# pse84 register map
Vendor: Cypress Semiconductor; Series: PSE84; File version: 1.0
CPU: CM33 r0p1, little endian, MPU, FPU, VTOR, 3 interrupt priority bits
Registers are 32-bit, read-write, reset 0x0 unless marked. A register's access mark holds for its fields unless they carry their own. Offsets are from the block's base; [hi:lo] are bit positions; lines under a group give offsets from that group; {n}, {i} and the like mark numbered series; 'fields as' and 'values as' point back to an identical list.

## SOCMEM — SoC memory
Base 0x44640000
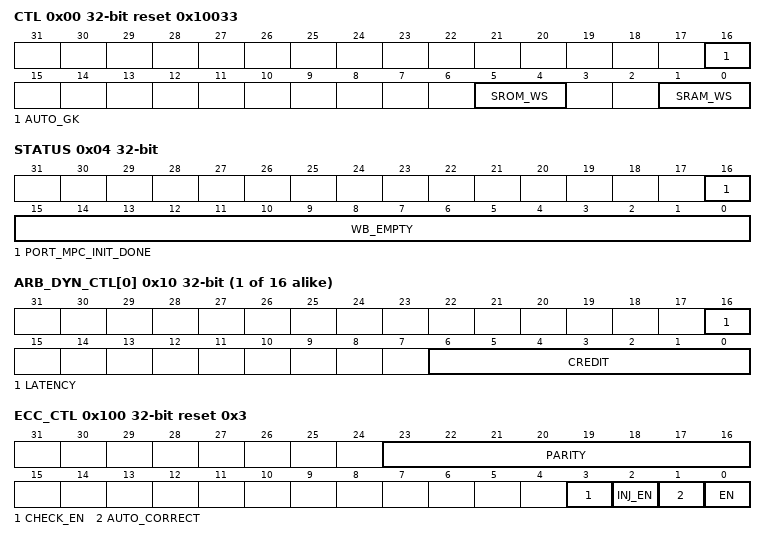
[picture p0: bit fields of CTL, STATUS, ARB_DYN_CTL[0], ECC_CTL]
0x00 CTL reset 0x10033 — Control
  [16] AUTO_GK — Automatic gate keeper control: '0': Disabled. '1': Enabled. Before every MMIO register write, ALL ports are automatically closed. After the MMIO register write, the gate keeper control defaults to GK_CTL.OPEN.
  [5:4] SROM_WS — Wait states.
    {v}=WS_{v} (N/A) (v=0..3)
  [1:0] SRAM_WS — Wait states.
    {v}=WS_{v} (N/A) (v=0..3)
0x04 STATUS ro (reset mask 0x10000)
  [16] PORT_MPC_INIT_DONE — Port MPC SRAM initialisation done. It is a combined single initialisation done for all the ports mpc sram.
  [15:0] WB_EMPTY — SRAM bank write buffer empty
0x08 GK_CTL — Gate keeper control
  [15:0] OPEN — Port gate keeper control: '0': Close port request. Finishes ongoing AMBA transactions, but does not accept new AMBA transactions. '1': Open port request. Note: GK_CTL allows for the creation of atomic sequences (from the perspective of AMBA transactions) of MMIO register writes. Note: gate keeper control is used to change MMIO register settings in an active system (per TZC400).
0x0C GK_STATUS ro — Gate keeper status
  [15:0] OPEN — Port gate keeper status '0': Port is closed. A port may be closed under SW MMIO control (GK_CTL) or under HW system control '1': Port is open. Note: gate keeper control is used to change MMIO register settings in an active system (per TZC400).
{0x10+4i} ARB_DYN_CTL[{i}] (i=0..15) — Port arbitration control
  [16] LATENCY — Specifies if the port is latency sensitive. '0': Non latency sensitive or less latency sensitive (e.g. a DMA controller). '1': Latency sensitive (e.g. a CPU or a real-time master such as a sound or display controller). As described above, the scheduler favors latency sensitive masters over non latency sensitive masters.
  [6:0] CREDIT — Port account increment. Value in the range [0, 127]. Total available SRAM/SROM bank bandwidth is partitioned into 128 partitions. The CREDIT value specifies what guaranteed relative bandwidth is assigned to the port. E.g., when CREDIT is '32', 25 percent of the relative bandwidth is assigned to the port. Note that for absolute bandwidth, the SRAM/SROM frequency and wait states need to be taken into account as well. An arbiter/scheduler operation is performed when one or more port requests for a SRAM/SROM bank are present and the SRAM/SROM bank is available for a new request. Each SRAM/SROM bank has a dedicated scheduler. The scheduler uses port account values: 9-bit values in the range [0, 511]. The port account values identify: - Non credit-worthy ports (account value in the range [0, 255]). - Credit-worthy ports (account value in the range [256, 511]). In addition, each port is specified to be either non (less) latency sensitive or latency sensitive (LATENCY). A scheduler operation is defined as follows: IF ('Any requesting port is a credit-worthy, latency port') 'Select port with lowest index from requesting, credit-worthy, latency ports' ELSE IF ('Any requesting port is a credit-worthy, non latency port') 'Select port with lowest index from requesting, credit-worthy, non latency ports' ELSE IF ('Any requesting port is a non credit-worthy, latency port') 'Select port with lowest index from requesting, non credit-worthy, latency ports' ELSE IF ('Any requesting port is a non credit-worthy, non latency port') 'Select port with lowest index from requesting, non credit-worthy, non latency ports' After a scheduler operation, account values are updated: - The selected port's account is incremented by CREDIT and decremented with '128'. If ECC is enabled AND the transaction was a partial write, an additional '128' is decremented, because two transactions (read-modify-write) are needed to change the ECC. Clipping to '0' is performed to prevent negative values. - Non-selected port account are increment by CREDIT, if the current account value is less than '256'. Otherwise, the port account value is not updated.
0x60 MPC_READ_PORT_CTL — MPC MMIO read port index control
  [3:0] INDEX — specifies port index for any MPC read access using SOCMEM.SRAM_MPC/SROM_MPC. 0- Any SW MPC MMIO read through SOCMEM.SRAM/SROM_MPC is from port-0. 1- Any SW MPC MMIO read through SOCMEM.SRAM/SROM_MPC is from port-1. . . 15- Any SW MPC MMIO read through SOCMEM.SRAM/SROM_MPC is from port-15. Note that INDEX field value programmed by SW must be between 0 and one less than number of configured SOCMEM ports (number of ports is design time config option using parameter PORT_NR). IMPORTANT: When MPC.CTRL.AUTO_INC is 1, each read access will auto-increment MPC.BLK_IDX in the port specified by MPC_READ_PORT_CTL.INDEX; not all ports are updated. Each write access will auto-increment MPC.BLK_IDX.VALUE in all ports. When MPC.CTRL.AUTO_INC is 1, to ensure that all ports are initialized correctly, write to MPC.BLK_IDX.VALUE before any series of writes to MPC.BLK_LUT. Writing to MPC.BLK_IDX.VALUE sets the index in all ports to the same value.
0x100 ECC_CTL reset 0x3 — ECC control
  [23:16] PARITY — Injected parity.
  [3] CHECK_EN — ECC checking enable: '0': Disabled. No ECC checking and associated bus errors. No fault reporting. Intended for SRAM initialization. '1': Enabled. Note: This field is ignored when EN is '0'.
  [2] INJ_EN — ECC parity injection: '0': Disabled. '1': Enabled. Instead of calculating the parity from the transfer's write data, the parity is taken from PARITY upon a match of the transfer's write address with ECC_MATCH.WORD_ADDR (no match is performed on the transfer's write strobes/mask). Note: Parity injection invalidates the write buffer for this word address. If only a part of 64-bit data word is written AND consistency should be maintained, STATUS.ALL_WB_EMPTY is '1' should be checked before. Note: This field is ignored when EN is '0'.
  [1] AUTO_CORRECT — ECC auto correction: '0': Disabled. Corrected ECC errors are ONLY HW corrected 'on-the-fly' (not corrected in the SRAM). Fault reporting is enabled. '1': Enabled. Correctable ECC errors are HW corrected 'on-the-fly' and in the SRAM, without CPU intervention. Fault reporting is enabled. Note: This field is ignored when EN is '0' or when CHECK_EN is '0'.
  [0] EN — ECC enable: '0': Disabled. '1': Enabled.
    0=ECC_DISABLED (N/A); 1=ECC_ENABLED (N/A)
0x104 ECC_MATCH
  [23:3] WORD_ADDR — Specifies the 8-Byte word address where a specific parity is injected. - On a write transfer to this word address, the parity (ECC_CTL.PARITY) is injected (if ECC_CTL.INJ_EN is '1').
0x110 WOUNDING
  [2:0] WOUND — Indicates the amount of accessible SRAM in this device. The value in this field is effectively write-once (it is only possible to set bits to '1', not clear them to '0'). Accesses to non-accessible SRAM return a bus error. Wounding control is rounded to next power of two bytes. '0': entire memory accessible '1': first 1/2 of the memory accessible. '2': first 1/4 of the memory accessible. '3': first 1/8 of the memory accessible. '4': first 1/16 of the memory accessible. '5': first 1/32 of the memory accessible. '6': first 1/64 of the memory accessible. '7': first 1/128 of the memory accessible.
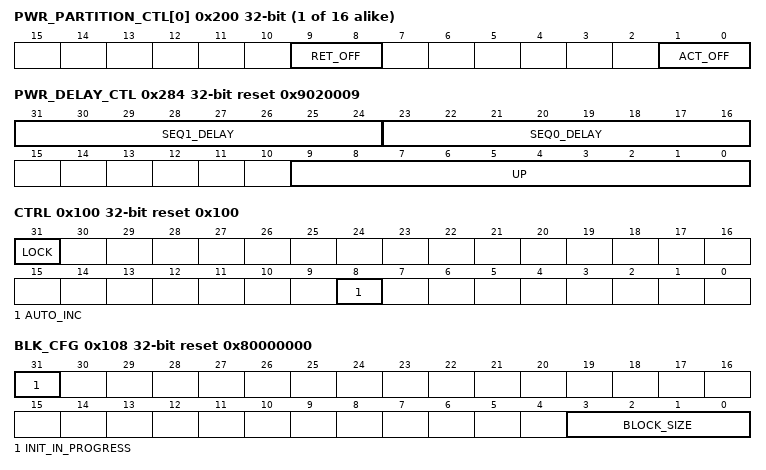
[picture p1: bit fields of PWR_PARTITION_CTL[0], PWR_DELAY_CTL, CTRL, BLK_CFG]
{0x200+4i} PWR_PARTITION_CTL[{i}] (i=0..15) — SRAM partition power control
  [9:8] RET_OFF, [1:0] ACT_OFF
0x280 PWR_PARTITION_CTL_LOCK reset 0x3 — SRAM power partition control Lock
  [1:0] PWR_PARTITION_CTL_LOCK — Prohibits Read/Write access to PWR_PARTITION_CTL register when this field is not equal to 0. Requires at least two different writes to unlock. Note that this field is 2 bits to force multiple writes only. By default AHB reads/writes to PWR_PARTITION_CTL register are locked.
    0=NO_CHG (No effect); 1=CLR0 (Clears bit 0); 2=CLR1 (Clears bit 1); 3=SET01 (Sets both bits 0 and 1)
0x284 PWR_DELAY_CTL reset 0x9020009 — SRAM power switch power up & sequence delay
  [31:24] SEQ1_DELAY — Number of IMO clock cycles delay needed for sequence-1 of SRAM power transition
  [23:16] SEQ0_DELAY — Number of IMO clock cycles delay needed for sequence-0 of SRAM power transition
  [9:0] UP — Number of IMO clock cycles delay needed after power domain power up
0x288 PWR_STATUS ro reset 0x1 — SRAM power status
  [0] PWR_DONE — After a PWR_PARTITION_CTL.OFF change this flag indicates if the new power mode has taken effect or not. 1: Indicates change is effective; 0: Indicates change is in progress;
0x2000 SRAM group — SRAM MPC
  0x00 MPC group — MPC Memory Protection Controller registers
    0x00 CFG — Config register with error response, RegionID PPC_MPC_MAIN is the security owner PC. The error response configuration is located in CFG.RESPONSE, only one such configuration exists applying to all protection contexts in the system.
      [4] RESPONSE — Response Configuration for Security and PC violations 0: Read-Zero Write Ignore (RAZ/WI) 1: Bus Error
    0x100 CTRL reset 0x100 — Control register with lock bit and auto-increment only (Separate CTRL for each PC depends on access_pc)
      [31] LOCK — Security lockdown for this protection context. Software can set this bit but not clear it once set. When set, write operations to BLK_LUT are not possible from this protection context. Setting LOCK also blocks writes to CTRL itself (for that PC copy). All writes are ignored.
      [8] AUTO_INC — Auto-increment BLK_IDX by 1 for this protection context as a side effect of each read/write access to BLK_LUT
    0x104 BLK_MAX ro — Max value of block-based index register
      [31:0] VALUE — Maximum value of block-based index register. The number and size blocks in an MPC is design time configurable and for embedded memories defaults to covering the entire memory using 4kB blocks; See product datasheet for details on protection of external memories.
    0x108 BLK_CFG ro reset 0x80000000 — Block size & initialization in progress
      [31] INIT_IN_PROGRESS — During initialization INIT_IN_PROGRESS is '1' and MMIO register accesses to BLK_LUT is blocked (BLK_IDX increment is also ignored). The block attributes are retained in DeepSleep (and obviously Active) power mode. Initialization is only required from a power mode in which the block attributes are not retained. E.g., initialization is required for a cold boot (after a Power-on-Reset). HW initializes the block attributes: the NS attributes are set to '0' (secure), the R attributes are set to '1' (read access allowed) and the W attributes are set to '1' (write access allowed). During initialization, the MPC supports memory accesses (memory accesses are NOT blocked) with the initialization block attribute values as mentioned above. This e.g. allows MPC initialization to proceed in parallel with boot program memory accesses (as opposed to serializing the two), improving device boot time.
      [3:0] BLOCK_SIZE — Block size of individually protected blocks (0: 32B, 1: 64B, ... up to 15: 1MB) Block size= (1<<(BLOCK_SIZE+5)) The number and size blocks in an MPC is design time configurable and for embedded memories defaults to covering the entire memory using 4kB blocks; see product datasheet for details on protection of external memories.
    0x10C BLK_IDX — Index of 32-block group accessed through BLK_LUT (Separate IDX for each PC depending on access_pc)
      [31:0] VALUE — Index value for accessing block-based lookup table using BLK_LUT. Programming out of LUT range is an user error and it loops back to '0' once overflow occurs.
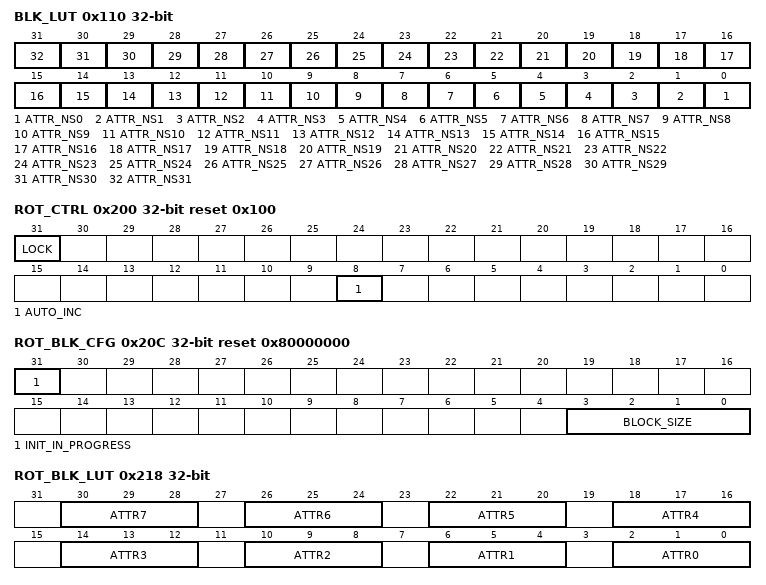
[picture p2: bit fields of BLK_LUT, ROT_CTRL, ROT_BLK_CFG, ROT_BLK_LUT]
    0x110 BLK_LUT — NS status for 32 blocks at BLK_IDX with PC=<access_pc>
      [n] ATTR_NS{n} (n=0..31) — NS bit for block {n} based on BLK_IDX
    0x200 ROT_CTRL reset 0x100 — Control register with lock bit and auto-increment only
      [31] LOCK — Security lockdown for the root-of-trust configuration registers. Software can set this bit but not clear it once set. When set, write operations to ROT_BLK_LUT are not possible. Write is ignored.
      [8] AUTO_INC — Auto-increment BLK_IDX by 1 for each read/write of ROT_BLK_LUT
    0x208 ROT_BLK_MAX ro — Max value of block-based index register for ROT
      [31:0] VALUE — Maximum value of block-based index register. The number and size blocks in an MPC is design time configurable and for embedded memories defaults to covering the entire memory using 4kB blocks; see product datasheet for details on protection of external memories.
    0x20C ROT_BLK_CFG ro reset 0x80000000 — Same as BLK_CFG
      [31] INIT_IN_PROGRESS — During initialization INIT_IN_PROGRESS is '1' and MMIO register accesses to ROT_BLK_LUT is RAZWI. The block attributes are retained in DeepSleep (and obviously Active) power mode. Initialization is only required from a power mode in which the block attributes are not retained. E.g., initialization is required for a cold boot (after a Power-on-Reset). HW initializes the block attributes: the NS attributes are set to '0' (secure), the R attributes are set to '1' (read access allowed) and the W attributes are set to '1' (write access allowed). During initialization, the MPC supports memory accesses (memory accesses are NOT blocked) with the initialization block attribute values as mentioned above. This e.g. allows MPC initialization to proceed in parallel with boot program memory accesses (as opposed to serializing the two), improving device boot time.
      [3:0] BLOCK_SIZE — Block size of individually protected blocks (0: 32B, 1: 64B, ...up to 15:1MB) Block size= (1<<(BLOCK_SIZE+5)) The number and size blocks in an MPC is design time configurable and for embedded memories defaults to covering the entire memory using 4kB blocks; see product datasheet for details on protection of external memories.
    0x210 ROT_BLK_IDX — Index of 8-block group accessed through ROT_BLK_LUT_*
      [31:0] VALUE — Index value for accessing block-based lookup table using ROT_BLK_LUT. Programming out of LUT range is an user error and it loops back to '0' once overflow occurs.
    0x214 ROT_BLK_PC — Protection context of 8-block group accesses through ROT_BLK_LUT
      [3:0] PC — Specify PC values for ROT_BLK_IDX and ROT_BLK_LUT
    0x218 ROT_BLK_LUT — (R,W,NS) bits for 8 blocks at ROT_BLK_IDX for PC=ROT_BKL_PC
      [4n+2:4n] ATTR{n} (n=0..7) — W/R/NS bits for block {n} indicated by ROT_BLK_IDX for ROT_BLK_PC PC
0x3000 SROM group — SROM MPC
  0x00 MPC group — MPC Memory Protection Controller registers
    0x00 CFG — Config register with error response, RegionID PPC_MPC_MAIN is the security owner PC. The error response configuration is located in CFG.RESPONSE, only one such configuration exists applying to all protection contexts in the system.
      fields as SRAM.MPC.CFG
    0x100 CTRL reset 0x100 — Control register with lock bit and auto-increment only (Separate CTRL for each PC depends on access_pc)
      fields as SRAM.MPC.CTRL
    0x104 BLK_MAX ro — Max value of block-based index register
      fields as SRAM.MPC.BLK_MAX
    0x108 BLK_CFG ro reset 0x80000000 — Block size & initialization in progress
      fields as SRAM.MPC.BLK_CFG
    0x10C BLK_IDX — Index of 32-block group accessed through BLK_LUT (Separate IDX for each PC depending on access_pc)
      fields as SRAM.MPC.BLK_IDX
    0x110 BLK_LUT — NS status for 32 blocks at BLK_IDX with PC=<access_pc>
      [n] ATTR_NS{n} (n=0..31) — NS bit for block {n} based on BLK_IDX
    0x200 ROT_CTRL reset 0x100 — Control register with lock bit and auto-increment only
      fields as SRAM.MPC.ROT_CTRL
    0x208 ROT_BLK_MAX ro — Max value of block-based index register for ROT
      fields as SRAM.MPC.ROT_BLK_MAX
    0x20C ROT_BLK_CFG ro reset 0x80000000 — Same as BLK_CFG
      fields as SRAM.MPC.ROT_BLK_CFG
    0x210 ROT_BLK_IDX — Index of 8-block group accessed through ROT_BLK_LUT_*
      fields as SRAM.MPC.ROT_BLK_IDX
    0x214 ROT_BLK_PC — Protection context of 8-block group accesses through ROT_BLK_LUT
      [3:0] PC — Specify PC values for ROT_BLK_IDX and ROT_BLK_LUT
    0x218 ROT_BLK_LUT — (R,W,NS) bits for 8 blocks at ROT_BLK_IDX for PC=ROT_BKL_PC
      fields as SRAM.MPC.ROT_BLK_LUT
{0x10000+0x1000*i} PORT_STRUCT[{i}] (i=0..4) group — Port structure
  0x00 PATCH_CTL — Patch control
    [31] ENABLED — Patching enable: '0': Disabled. '1': Enabled.
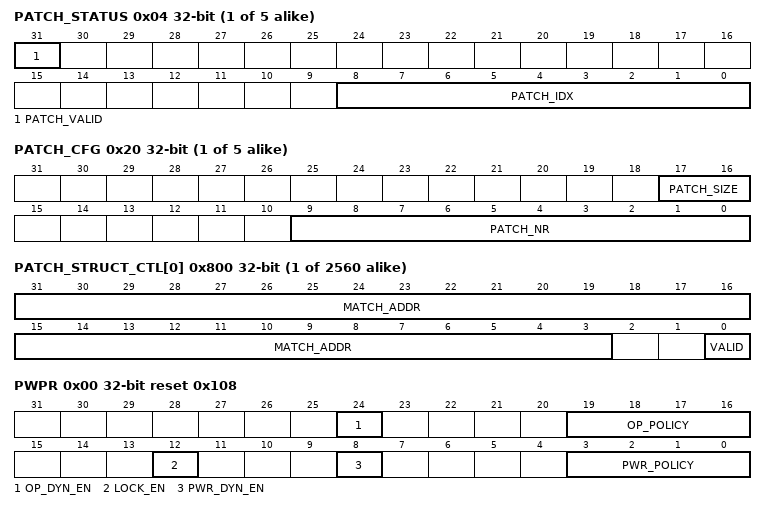
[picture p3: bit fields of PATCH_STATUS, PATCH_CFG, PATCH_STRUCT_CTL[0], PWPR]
  0x04 PATCH_STATUS ro (reset mask 0x80000000)
    [31] PATCH_VALID — Validity of PATCH_IDX: '0': Not valid. '1': Valid.
    [8:0] PATCH_IDX — Match index of the patch structure that produced the most recent valid address match. The index is in the range [0, PATCH_NR-1].
  0x10 PATCH_SROM — Patch SROM boundary
    [31:0] BOUNDARY — Specifies the boundary between non-patchable and patchable SROM memory locations (the address specifies the first patchable SROM memory location). The SROM is divided into two partitions: - The first/lower partition is non-patchable. This partition may be used to provide an immutable 'root of trust'. - The second/high partition is patchable. This partition may be used for FW that requires updates. Note: Higher bit indices reflect the SROM location in the memory map. When BOUNDARY equals the SROM base address, the complete SROM is patchable. When ADDR equal the SROM base address plus the SROM size, the complete SROM is non-patchable.
  0x14 PATCH_SRAM — Patch SRAM address
    [31:0] ADDR — Patch address. This address is the start/base address of a SRAM memory region that holds the patch data. The address should be aligned. Specifically, the address is a multiple of the patch data memory region size. The patch data memory size is defined as follows: PATCH_NR * PATCH_SIZE Bytes (assuming PATCH_NR is a power of two)
  0x20 PATCH_CFG ro — Patch configuration
    [17:16] PATCH_SIZE — Patch size; i.e. number of Bytes that are 'patched' by a single patch structure: '0': 8 Bytes. '1': 16 Bytes. '2': 32 Bytes. '3': 64 Bytes.
    [9:0] PATCH_NR — Patch number; i.e. number of patch structures. Legal range: [0, 512].
  {0x800+4j} PATCH_STRUCT_CTL[{j}] (j=0..511) (reset mask 0x1) — Patch structure control
    [31:3] MATCH_ADDR — Match address. SROM accesses are matched/compared to this address. An address match results into patching/redirection of the SROM access (if PATCH_CTL.ENABLED is '1'): the SROM access is redirected to an SRAM access. The PATCH_SRAM register and the 'matching' patch structure index determine the SRAM access address. Specifically, given an index i, the SRAM access address is given by: PATCH_SRAM.ADDR + i * 'patch size', where patch size is the number of Bytes that are patched by a single patch structure (2 ^ (3+CFG.PATCH_SIZE)). The MATCH_ADDR[] bit range is dependent on two design time configuration parameters: - The lowest index is determined by PATCH_SIZE. E.g., a 8 Byte patch size uses '3' as the lowest bit index, a 16 Byte patch size uses '4' as the lowest bit index, etc. Unused lower bit indices are '0'. - The highest index is determined by the SROM size as specified by SROM_MASK (the next power of two multiple of the SROM size). E.g., a 0xffff:0000 mask specifies a 64 KByte SROM size and uses '15' as the highest bit index, a 0xfff0:0000 mask specifies a 1 MByte SROM size and uses '19' as the highest bit index, etc. Unused higher bit indices reflect the SROM location in the address space.
    [0] VALID — Patch structure validity: '0': Not valid. '1': Valid. Note: VALID uses the bit field '0' location, rather than the more typical bit field '31' location. This architecture decision was made to allow for SROM location anywhere in a 32-bit address space, and not require extensive address manipulation when accessing PATCH_CTL.MATCH_ADDR.
0x20000 PPU_SOCMEM group — Power Policy Unit Registers for SOCMEM PPU
  0x00 PWPR reset 0x108 — Power Policy Register
    [24] OP_DYN_EN
    [19:16] OP_POLICY
    [12] LOCK_EN
    [8] PWR_DYN_EN — Power mode dynamic transition enable. When this bit is set to 1 dynamic transitions are enabled for power modes, allowing transitions to be initiated by changes on power mode DEVACTIVE inputs.
    [3:0] PWR_POLICY — Power mode policy. When static power mode transitions are enabled, PWR_DYN_EN is set to 0, this is the target power mode for the PPU. When dynamic power mode transitions are enabled, PWR_DYN_EN is set to 1, this is the minimum power mode for the PPU. This PPU supports the following modes: OFF(0), MEM_RET(2), ON(8). Do not use WARM_RST(9) or other unsupported modes.
  0x04 PMER — Power Mode Emulation Register
    [0] EMU_EN
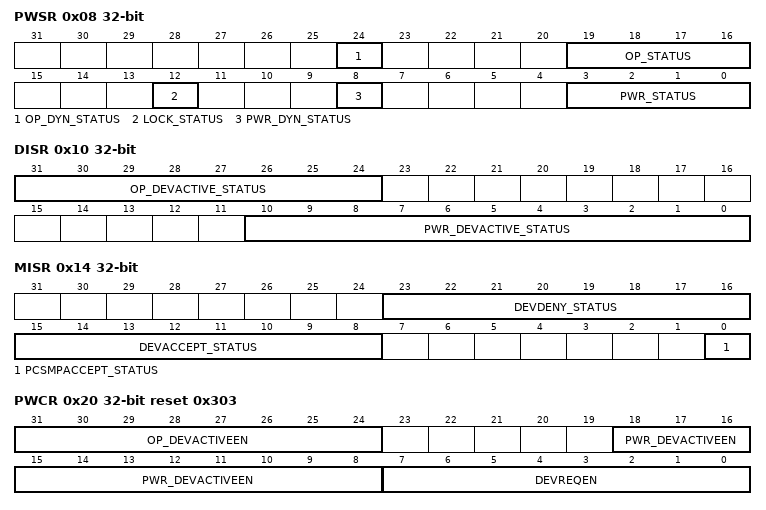
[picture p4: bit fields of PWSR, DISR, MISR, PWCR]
  0x08 PWSR ro — Power Status Register
    [24] OP_DYN_STATUS
    [19:16] OP_STATUS
    [12] LOCK_STATUS
    [8] PWR_DYN_STATUS — Power mode dynamic transition status. When set to 1 power mode dynamic transitions are enabled. There might be a delay in dynamic transitions becoming active or inactive if the PPU is transitioning when PWR_DYN_EN is programmed.
    [3:0] PWR_STATUS — Power mode status. These bits reflect the current power mode of the PPU. See PPU_PWPR.PWR_POLICY for power mode enumeration.
  0x10 DISR ro — Device Interface Input Current Status Register
    [31:24] OP_DEVACTIVE_STATUS
    [10:0] PWR_DEVACTIVE_STATUS — Status of the power mode DEVACTIVE inputs. There is one bit for each device interface Q-Channel DEVQACTIVE. For example, bit 0 is for Q-channel device 0 DEVQACTIVE. Refer to PPU_IDR0.DEVCHAN for device channel enumeration.
  0x14 MISR ro — Miscellaneous Input Current Status Register
    [23:16] DEVDENY_STATUS — Status of the device interface DEVDENY inputs. There is one bit for each device interface DEVQDENY. For example, bit 16 is for Q-Channel 0 DEVQDENY, and bit 17 for Q-Channel 1 DEVQDENY. Refer to PPU_IDR0.DEVCHAN for device channel enumeration.
    [15:8] DEVACCEPT_STATUS — Status of the device interface DEVACCEPT inputs. There is one bit for each device interface DEVQACCEPTn. For example, bit 8 is for Q-Channel 0 DEVQACCEPTn and bit 9 for Q-Channel 1 DEVQACCEPTn. Refer to PPU_IDR0.DEVCHAN for device channel enumeration.
    [0] PCSMPACCEPT_STATUS — The status of the PCSMPACCEPT input.
  0x18 STSR ro — Stored Status Register
    [7:0] STORED_DEVDENY
  0x1C UNLK — Unlock register
    [0] UNLOCK
  0x20 PWCR reset 0x303 — Power Configuration Register
    [31:24] OP_DEVACTIVEEN
    [18:8] PWR_DEVACTIVEEN — These bits enable the power mode DEVACTIVE inputs. When a bit is to 1 the related DEVACTIVE input is enabled, when set to 0 it is disabled. All available bits are reset to 1. There is one bit for each device interface Q-Channel DEVQACTIVE. For example, bit 8 is for the Q-Channel 0 DEVQACTIVE, and bit 9 for the Q-Channel 1 DEVQACTIVE. Refer to PPU_IDR0.DEVCHAN for device channel enumeration.
    [7:0] DEVREQEN — When set to 1 enables the device interface handshake for transitions. All available bits are reset to 1. There is one bit for each device interface channel. For example, bit 0 is for Q-Channel 0, and bit 1 is for Q-Channel 1. Refer to PPU_IDR0.DEVCHAN for device channel enumeration.
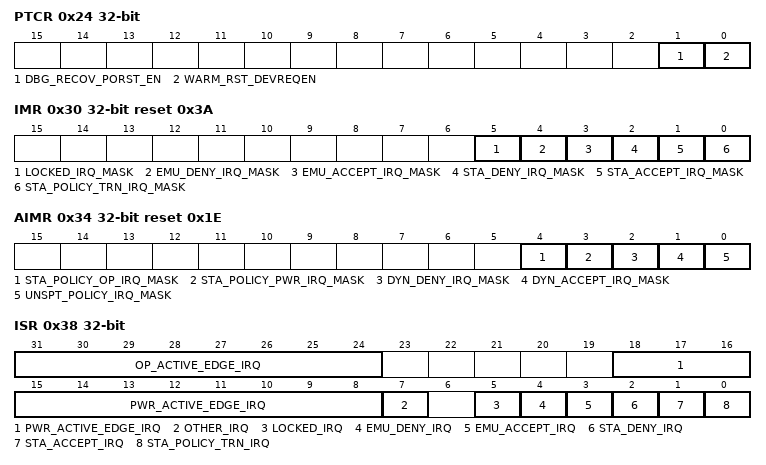
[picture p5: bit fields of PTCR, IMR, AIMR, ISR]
  0x24 PTCR — Power Mode Transition Configuration Register
    [1] DBG_RECOV_PORST_EN
    [0] WARM_RST_DEVREQEN — Transition behavior between ON and WARM_RST. This bit should not be modified when the PPU is in WARM_RST, or if the PPU is performing a transition, otherwise PPU behavior is UNPREDICTABLE. 0: The PPU does not perform a device interface handshake when transitioning between ON and WARM_RST. 1: The PPU performs a device interface handshake when transitioning between ON and WARM_RST. This disables all Q-Channels for this transition.
  0x30 IMR reset 0x3A — Interrupt Mask Register
    [5] LOCKED_IRQ_MASK
    [4] EMU_DENY_IRQ_MASK
    [3] EMU_ACCEPT_IRQ_MASK
    [2] STA_DENY_IRQ_MASK — Static transition denial event mask.
    [1] STA_ACCEPT_IRQ_MASK — Static transition acceptance event mask.
    [0] STA_POLICY_TRN_IRQ_MASK — Static full policy transition completion event mask.
  0x34 AIMR reset 0x1E — Additional Interrupt Mask Register
    [4] STA_POLICY_OP_IRQ_MASK
    [3] STA_POLICY_PWR_IRQ_MASK
    [2] DYN_DENY_IRQ_MASK — Dynamic transition denial event mask.
    [1] DYN_ACCEPT_IRQ_MASK — Dynamic transition acceptance event mask.
    [0] UNSPT_POLICY_IRQ_MASK — Unsupported Policy event mask.
  0x38 ISR — Interrupt Status Register
    [31:24] OP_ACTIVE_EDGE_IRQ
    [18:8] PWR_ACTIVE_EDGE_IRQ
    [7] OTHER_IRQ ro — Indicates there is an interrupt event pending in the Additional Interrupt Status Register (PPU_AISR).
    [5] LOCKED_IRQ
    [4] EMU_DENY_IRQ
    [3] EMU_ACCEPT_IRQ
    [2] STA_DENY_IRQ — Static transition denial event status.
    [1] STA_ACCEPT_IRQ — Static transition acceptance event status.
    [0] STA_POLICY_TRN_IRQ — Static full policy transition completion event status.
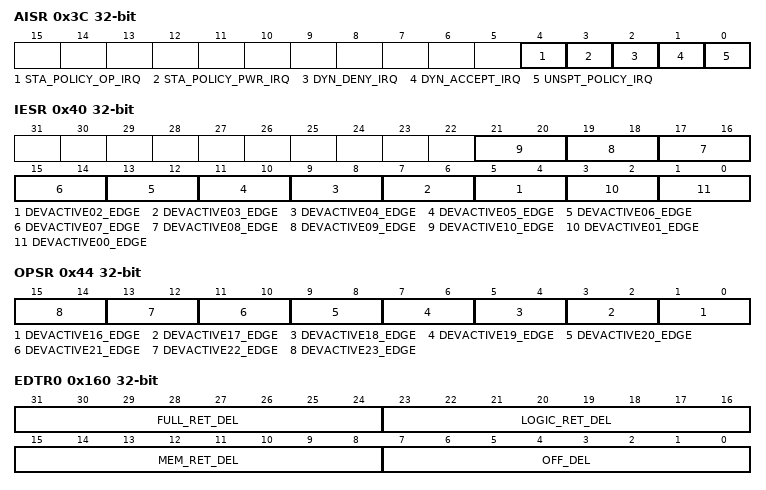
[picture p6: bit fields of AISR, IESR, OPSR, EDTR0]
  0x3C AISR — Additional Interrupt Status Register
    [4] STA_POLICY_OP_IRQ
    [3] STA_POLICY_PWR_IRQ
    [2] DYN_DENY_IRQ — Dynamic transition denial event status.
    [1] DYN_ACCEPT_IRQ — Dynamic transition acceptance event status.
    [0] UNSPT_POLICY_IRQ — Unsupported Policy event status.
  0x40 IESR — Input Edge Sensitivity Register
    [2n+1:2n] DEVACTIVE{n:02}_EDGE (n=2..10)
    [3:2] DEVACTIVE01_EDGE — DEVACTIVE 1 edge sensitivity.
    [1:0] DEVACTIVE00_EDGE — DEVACTIVE 0 edge sensitivity.
  0x44 OPSR — Operating Mode Active Edge Sensitivity Register
    [2n-31:2n-32] DEVACTIVE{n}_EDGE (n=16..23)
  0x50 FUNRR — Functional Retention RAM Configuration Register
    [7:0] FUNC_RET_RAM_CFG
  0x54 FULRR — Full Retention RAM Configuration Register
    [7:0] FULL_RET_RAM_CFG
  0x58 MEMRR — Memory Retention RAM Configuration Register
    [7:0] MEM_RET_RAM_CFG
  0x160 EDTR0 — Power Mode Entry Delay Register 0
    [31:24] FULL_RET_DEL, [23:16] LOGIC_RET_DEL, [15:8] MEM_RET_DEL, [7:0] OFF_DEL
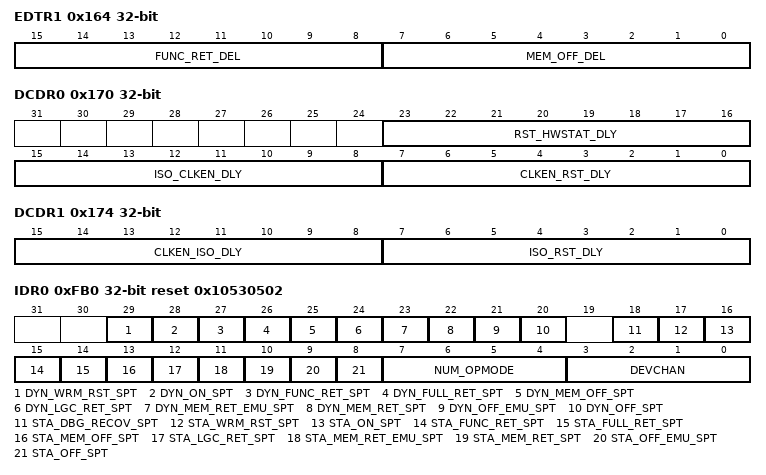
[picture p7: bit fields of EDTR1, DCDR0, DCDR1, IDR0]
  0x164 EDTR1 — Power Mode Entry Delay Register 1
    [15:8] FUNC_RET_DEL, [7:0] MEM_OFF_DEL
  0x170 DCDR0 ro — Device Control Delay Configuration Register 0
    [23:16] RST_HWSTAT_DLY, [15:8] ISO_CLKEN_DLY, [7:0] CLKEN_RST_DLY
  0x174 DCDR1 ro — Device Control Delay Configuration Register 1
    [15:8] CLKEN_ISO_DLY, [7:0] ISO_RST_DLY
  0xFB0 IDR0 ro reset 0x10530502 — PPU Identification Register 0
    [29] DYN_WRM_RST_SPT — Dynamic WARM_RST support.
    [28] DYN_ON_SPT — Dynamic ON support.
    [27] DYN_FUNC_RET_SPT — Dynamic FUNC_RET support.
    [26] DYN_FULL_RET_SPT — Dynamic FULL_RET support.
    [25] DYN_MEM_OFF_SPT — Dynamic MEM_OFF support.
    [24] DYN_LGC_RET_SPT — Dynamic LOGIC_RET support.
    [23] DYN_MEM_RET_EMU_SPT — Dynamic MEM_RET_EMU support
    [22] DYN_MEM_RET_SPT — Dynamic MEM_RET support.
    [21] DYN_OFF_EMU_SPT — Dynamic OFF_EMU support.
    [20] DYN_OFF_SPT — Dynamic OFF support.
    [18] STA_DBG_RECOV_SPT — DBG_RECOV support.
    [17] STA_WRM_RST_SPT — WARM_RST support. Ignore this bit. Do not use WARM_RST.
    [16] STA_ON_SPT — ON support.
    [15] STA_FUNC_RET_SPT — FUNC_RET support.
    [14] STA_FULL_RET_SPT — FULL_RET support.
    [13] STA_MEM_OFF_SPT — MEM_OFF support.
    [12] STA_LGC_RET_SPT — LOGIC_RET support.
    [11] STA_MEM_RET_EMU_SPT — MEM_RET_EMU support.
    [10] STA_MEM_RET_SPT — MEM_RET support.
    [9] STA_OFF_EMU_SPT — OFF_EMU support.
    [8] STA_OFF_SPT — OFF support.
    [7:4] NUM_OPMODE — No. of operating modes supported is NUM_OPMODE + 1.
    [3:0] DEVCHAN — No. of Device Interface Channels. The device enumeration is: Device 0: SOCMEM SEQ between between SOCMEM MMIO, ports & Banks. Device 1: SRSS PDCM
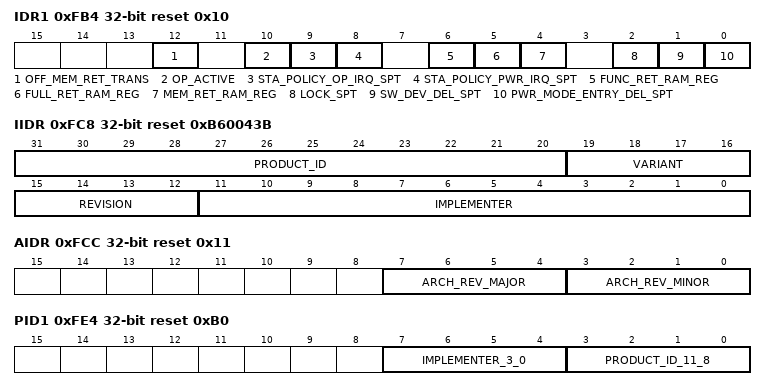
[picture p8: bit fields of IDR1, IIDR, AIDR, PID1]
  0xFB4 IDR1 ro reset 0x10 — PPU Identification Register 1
    [12] OFF_MEM_RET_TRANS — OFF to MEM_RET direct transition. Indicates if direct transitions from OFF to MEM_RET and from OFF_EMU to MEM_RET_EMU are supported.
    [10] OP_ACTIVE
    [9] STA_POLICY_OP_IRQ_SPT — Operating policy transition completion event status.
    [8] STA_POLICY_PWR_IRQ_SPT — Power policy transition completion event status.
    [6] FUNC_RET_RAM_REG
    [5] FULL_RET_RAM_REG
    [4] MEM_RET_RAM_REG
    [2] LOCK_SPT — Lock and the lock interrupt event are supported.
    [1] SW_DEV_DEL_SPT — Software device delay control configuration support.
    [0] PWR_MODE_ENTRY_DEL_SPT — Power mode entry delay support.
  0xFC8 IIDR ro reset 0xB60043B — Implementation Identification Register
    [31:20] PRODUCT_ID — PPU part identification.
    [19:16] VARIANT — Major revision of the product.
    [15:12] REVISION — Minor revision of the product.
    [11:0] IMPLEMENTER — Implementer identification. [11:8] The JEP106 continuation code of the implementer. [7] Always 0. [6:0] The JEP106 identity code of the implementer. For an Arm implementation, bits [11:0] are 0x43B.
  0xFCC AIDR ro reset 0x11 — Architecture Identification Register
    [7:4] ARCH_REV_MAJOR, [3:0] ARCH_REV_MINOR
  0xFD0 PID4 ro reset 0x4 — Implementation Defined Identification Register (PID4)
    [3:0] IMPLEMENTER_11_8 — The JEP106 continuation code of the implementer, which is 0x4 hardcoded value.
  0xFE0 PID0 ro reset 0xB6 — Implementation Defined Identification Register (PID0)
    [7:0] PRODUCT_ID_7_0 — PPU part identification bits [7:0].
  0xFE4 PID1 ro reset 0xB0 — Implementation Defined Identification Register (PID1)
    [7:4] IMPLEMENTER_3_0 — JEP106_ID bits [3:0]
    [3:0] PRODUCT_ID_11_8 — PPU part identification bits [11:8]
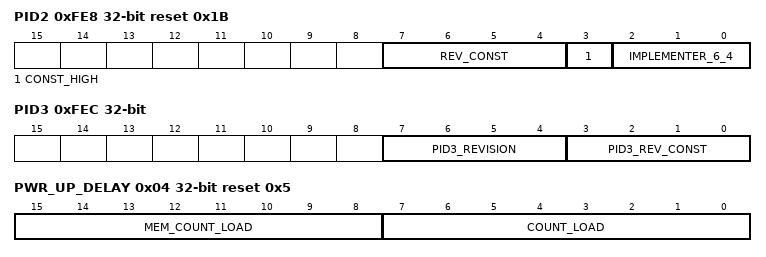
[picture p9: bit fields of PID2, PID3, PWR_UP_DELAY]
  0xFE8 PID2 ro reset 0x1B — Implementation Defined Identification Register (PID2)
    [7:4] REV_CONST — Constant LOW Revision (4 bits)
    [3] CONST_HIGH — Constant HIGH
    [2:0] IMPLEMENTER_6_4 — JEP106_ID bits [6:4]
  0xFEC PID3 ro — Implementation Defined Identification Register (PID3)
    [7:4] PID3_REVISION — Minor revision of the product.
    [3:0] PID3_REV_CONST — Constant LOW (4 bits)
  0xFF0 ID0 ro reset 0xD — Implementation Defined Identification Register (ID0)
    [7:0] ID0 — ID0 hard coded value
  0xFF4 ID1 ro reset 0xF0 — Implementation Defined Identification Register (ID1)
    [7:0] ID1 — ID1 hardcoded value
  0xFF8 ID2 ro reset 0x5 — Implementation Defined Identification Register (ID2)
    [7:0] ID2 — ID2 hardcoded value
  0xFFC ID3 ro reset 0xB1 — Implementation Defined Identification Register (ID3)
    [7:0] ID3 — ID3 hardcoded value
0x21000 SOCMEM group — Power Domain controller
  0x00 PD group — Power Domain Controller
    0x00 CTL — Power Domain Control
      [0] BLEED_EN — Activates bleed feature for the controlled power domain
    0x04 PWR_UP_DELAY reset 0x5 — Active switch weak enable to active switch strong enable delay
      [15:8] MEM_COUNT_LOAD — Load value for counter running on clk_pwr (10MHz) providing the timing from weak MEM switch enable to strong MEM switch enable. Default is 5 for ~500ns
      [7:0] COUNT_LOAD — Load value for counter running on clk_pwr (10MHz) providing the timing from weak ACTIVE switch enable to strong ACTIVE switch enable. Default is 5 for ~500ns
